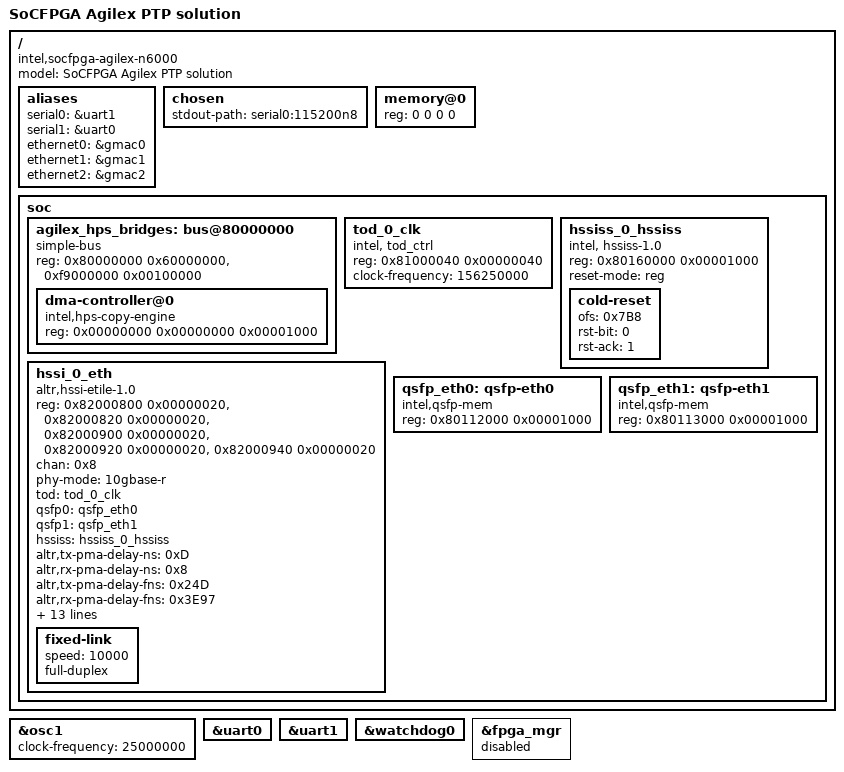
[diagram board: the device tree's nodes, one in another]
// SPDX-License-Identifier: GPL
/*
 * Copyright (C) 2022,2023 Intel Corporation
 */
#include "socfpga_agilex.dtsi"

/ {
	model = "SoCFPGA Agilex PTP solution";
        compatible = "intel,socfpga-agilex-n6000", "intel,socfpga-agilex";

        aliases {
                serial0 = &uart1;
                serial1 = &uart0;
                ethernet0 = &gmac0;
                ethernet1 = &gmac1;
                ethernet2 = &gmac2;
        };

        chosen {
                stdout-path = "serial0:115200n8";
        };

        memory@0 {
                device_type = "memory";
                /* We expect the bootloader to fill in the reg */
                reg = <0 0 0 0>;
        };

        soc {
                agilex_hps_bridges: bus@80000000 {
                        compatible = "simple-bus";
                        reg = <0x80000000 0x60000000>,
                              <0xf9000000 0x00100000>;
                        reg-names = "axi_h2f", "axi_h2f_lw";
                        #address-cells = <2>;
                        #size-cells = <1>;
            		ranges =        <0x00000000 0x00000000 0xf9000000 0x00001000>,
                                        <0x00000001 0x00000000 0x80000000 0x00040000>;

                        dma-controller@0 {
                                compatible = "intel,hps-copy-engine";
                                reg = <0x00000000 0x00000000 0x00001000>;
                                #dma-cells = <1>;
                        };
        };
		tod_0_clk: tod_0_clk{
			compatible = "intel, tod_ctrl";
			reg-names = "tod_ctrl";
			reg = <0x81000040 0x00000040>;
			clock-frequency = <156250000>;
			status = "okay";
		};


	         hssiss_0_hssiss: hssiss_0_hssiss {
			compatible = "intel, hssiss-1.0";
			reg-names = "sscsr";
			reg = <0x80160000 0x00001000>;
                        reset-mode ="reg";
                        cold-reset {
                                ofs = <0x7B8>;
                                rst-bit = <0>;
                                rst-ack = <1>;
			};
		};

		hssi_0_eth: hssi_0_eth{

				reg-names = "tx_pref"  , 
					    "tx_csr"   , 
					    "rx_pref"  , 
					    "rx_csr"   , 
					    "rx_fifo"  ;

				reg =   <0x82000800 0x00000020>,
					<0x82000820 0x00000020>,
					<0x82000900 0x00000020>,
					<0x82000920 0x00000020>,
					<0x82000940 0x00000020>;

				compatible = "altr,hssi-etile-1.0";
				chan = <0x8>;
				phy-mode = "10gbase-r";
				tod = <&tod_0_clk>;
				qsfp0 = <&qsfp_eth0>;
				qsfp1 = <&qsfp_eth1>;
				hssiss = <&hssiss_0_hssiss>;
				clock-names = "tod_clk";
				altr,tx-pma-delay-ns = <0xD>;
				altr,rx-pma-delay-ns = <0x8>;
				altr,tx-pma-delay-fns = <0x24D>;
				altr,rx-pma-delay-fns = <0x3E97>;
				altr,tx-external-phy-delay-ns = <0x0>;
				altr,rx-external-phy-delay-ns = <0x0>;
				fec-cw-pos-rx = <0x3>;
				fec-type="no-fec";
				interrupt-parent = <&intc>;
				interrupt-names = "tx_irq", "rx_irq";
				interrupts = <0 24 4>, <0 25 4>;
				qsfp-lane = <0x0>;
				rx-fifo-depth = <0x4000>;
				tx-fifo-depth = <0x1000>;
				rx-fifo-almost-full = <0x2000>;
				rx-fifo-almost-empty = <0x1000>;
				altr,has-ptp;
				altr,has-ptp-clockcleaner;
				status = "okay";
				fixed-link {
					speed =<10000>;
					full-duplex;
				};
			};

                qsfp_eth0: qsfp-eth0 {
                        compatible = "intel,qsfp-mem";
                        reg-names = "qsfp-mem-ctrl";
                        reg = <0x80112000 0x00001000>;
                        status = "okay";
                };


                qsfp_eth1: qsfp-eth1 {
                        compatible = "intel,qsfp-mem";
                        reg-names = "qsfp-mem-ctrl";
                        reg = <0x80113000 0x00001000>;
                        status = "okay";
                };
        };
};

&osc1 {
        clock-frequency = <25000000>;
};

&uart0 {
        status = "okay";
};

&uart1 {
        status = "okay";
};

&watchdog0 {
        status = "okay";
};

&fpga_mgr {
        status = "disabled";
};

